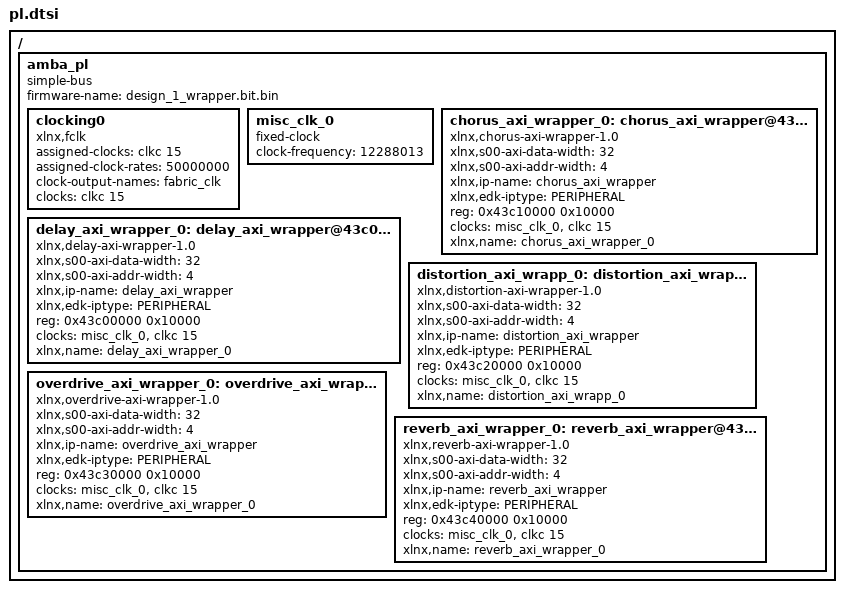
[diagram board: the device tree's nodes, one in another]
/ {
	amba_pl: amba_pl {
		ranges;
		compatible = "simple-bus";
		#address-cells = <1>;
		#size-cells = <1>;
		firmware-name = "design_1_wrapper.bit.bin";
		clocking0: clocking0 {
			compatible = "xlnx,fclk";
			assigned-clocks = <&clkc 15>;
			assigned-clock-rates = <50000000>;
			#clock-cells = <0>;
			clock-output-names = "fabric_clk";
			clocks = <&clkc 15>;
		};
		misc_clk_0: misc_clk_0 {
			compatible = "fixed-clock";
			clock-frequency = <12288013>;
			#clock-cells = <0>;
		};
		chorus_axi_wrapper_0: chorus_axi_wrapper@43c10000 {
			xlnx,s00-axi-data-width = <32>;
			compatible = "xlnx,chorus-axi-wrapper-1.0";
			status = "okay";
			clock-names = "audio_clk" , "s00_axi_aclk";
			xlnx,s00-axi-addr-width = <4>;
			xlnx,ip-name = "chorus_axi_wrapper";
			xlnx,edk-iptype = "PERIPHERAL";
			reg = <0x43c10000 0x10000>;
			clocks = <&misc_clk_0>, <&clkc 15>;
			xlnx,name = "chorus_axi_wrapper_0";
		};
		delay_axi_wrapper_0: delay_axi_wrapper@43c00000 {
			xlnx,s00-axi-data-width = <32>;
			compatible = "xlnx,delay-axi-wrapper-1.0";
			status = "okay";
			clock-names = "audio_clk" , "s00_axi_aclk";
			xlnx,s00-axi-addr-width = <4>;
			xlnx,ip-name = "delay_axi_wrapper";
			xlnx,edk-iptype = "PERIPHERAL";
			reg = <0x43c00000 0x10000>;
			clocks = <&misc_clk_0>, <&clkc 15>;
			xlnx,name = "delay_axi_wrapper_0";
		};
		distortion_axi_wrapp_0: distortion_axi_wrapper@43c20000 {
			xlnx,s00-axi-data-width = <32>;
			compatible = "xlnx,distortion-axi-wrapper-1.0";
			status = "okay";
			clock-names = "audio_clk" , "s00_axi_aclk";
			xlnx,s00-axi-addr-width = <4>;
			xlnx,ip-name = "distortion_axi_wrapper";
			xlnx,edk-iptype = "PERIPHERAL";
			reg = <0x43c20000 0x10000>;
			clocks = <&misc_clk_0>, <&clkc 15>;
			xlnx,name = "distortion_axi_wrapp_0";
		};
		overdrive_axi_wrapper_0: overdrive_axi_wrapper@43c30000 {
			xlnx,s00-axi-data-width = <32>;
			compatible = "xlnx,overdrive-axi-wrapper-1.0";
			status = "okay";
			clock-names = "audio_clk" , "s00_axi_aclk";
			xlnx,s00-axi-addr-width = <4>;
			xlnx,ip-name = "overdrive_axi_wrapper";
			xlnx,edk-iptype = "PERIPHERAL";
			reg = <0x43c30000 0x10000>;
			clocks = <&misc_clk_0>, <&clkc 15>;
			xlnx,name = "overdrive_axi_wrapper_0";
		};
		reverb_axi_wrapper_0: reverb_axi_wrapper@43c40000 {
			xlnx,s00-axi-data-width = <32>;
			compatible = "xlnx,reverb-axi-wrapper-1.0";
			status = "okay";
			clock-names = "audio_clk" , "s00_axi_aclk";
			xlnx,s00-axi-addr-width = <4>;
			xlnx,ip-name = "reverb_axi_wrapper";
			xlnx,edk-iptype = "PERIPHERAL";
			reg = <0x43c40000 0x10000>;
			clocks = <&misc_clk_0>, <&clkc 15>;
			xlnx,name = "reverb_axi_wrapper_0";
		};
	};
};
